# STM32F303xE register map
File version: 1.0
Registers are 32-bit, read-write, reset 0x0 unless marked. A register's access mark holds for its fields unless they carry their own. Offsets are from the block's base; [hi:lo] are bit positions; {n}, {i} and the like mark numbered series.

## SYSCFG — System configuration controller
Base 0x40010000
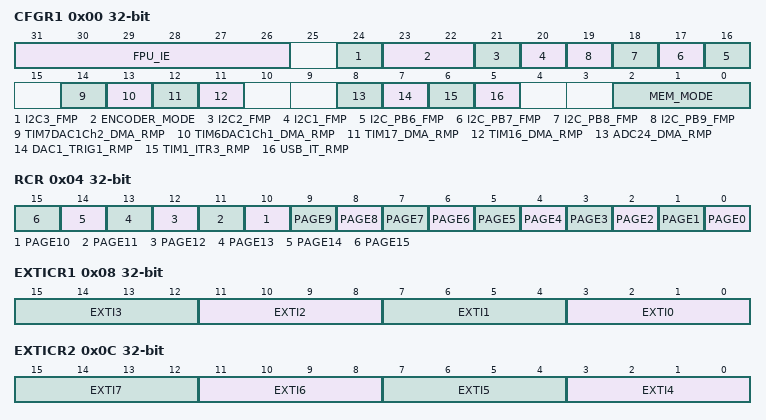
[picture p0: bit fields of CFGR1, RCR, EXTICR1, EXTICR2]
0x00 CFGR1 — SYSCFG configuration register 1
  [31:26] FPU_IE — Floating Point Unit Interrupt Enable
  [24] I2C3_FMP — I2C3 Fast mode plus
  [23:22] ENCODER_MODE
  [21] I2C2_FMP — I2C2 Fast mode plus
  [20] I2C1_FMP — I2C1 Fast mode plus
  [n+10] I2C_PB{n}_FMP (n=6..9) — I2C PB{n} Fast mode plus
  [14] TIM7DAC1Ch2_DMA_RMP — Timer 7 / DAC1 Ch2 DMA remap
  [13] TIM6DAC1Ch1_DMA_RMP — Timer 6 / DAC1 Ch1 DMA remap
  [12] TIM17_DMA_RMP — Timer 17 DMA remap
  [11] TIM16_DMA_RMP — Timer 16 DMA remap
  [8] ADC24_DMA_RMP — ADC2 and ADC4 DMA remap
  [7] DAC1_TRIG1_RMP — DAC1 Trigger1 remap
  [6] TIM1_ITR3_RMP — Timer 1 ITR3 selection
  [5] USB_IT_RMP — USB interrupt remap
  [2:0] MEM_MODE — SYSCFG_Memory Remap Config
    0=FLASH; 1=SYSTEMFLASH; 3=SRAM; 4=FMC
0x04 RCR — SYSCFG CCM SRAM protection register
  [n] PAGE{n} (n=0..15) — ICODE SRAM Write protection page {n}
0x08 EXTICR1 — SYSCFG external interrupt configuration registers
  [4n+3:4n] EXTI{n} (n=0..3) — EXTI {n} configuration
0x0C EXTICR2 — SYSCFG external interrupt configuration registers
  [4n-13:4n-16] EXTI{n} (n=4..7) — EXTI {n} configuration
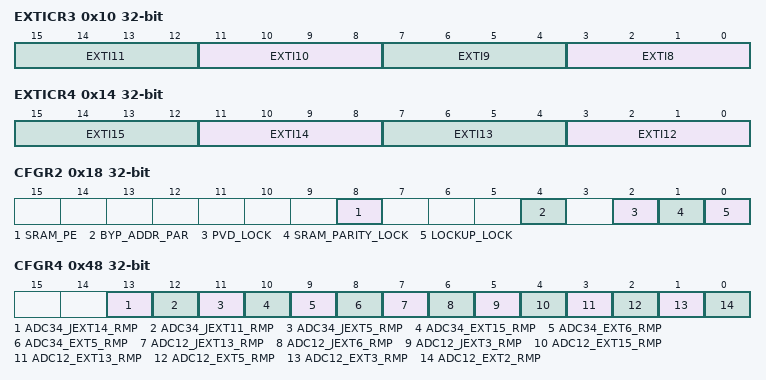
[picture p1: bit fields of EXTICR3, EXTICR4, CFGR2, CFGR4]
0x10 EXTICR3 — SYSCFG external interrupt configuration registers
  [4n-29:4n-32] EXTI{n} (n=8..11) — EXTI {n} configuration
0x14 EXTICR4 — SYSCFG external interrupt configuration registers
  [4n-45:4n-48] EXTI{n} (n=12..15) — EXTI {n} configuration
0x18 CFGR2 — SYSCFG configuration register 2
  [8] SRAM_PE — SRAM Parity error flag
  [4] BYP_ADDR_PAR — Disables the address parity check on RAM
  [2] PVD_LOCK — Enables and locks the PVD connection with TIMx Break Input, as well as the PVDE and PLS[2:0] in the PWR_CR register
  [1] SRAM_PARITY_LOCK — Enables and locks the SRAM_PARITY error signal with Break Input of TIMx
  [0] LOCKUP_LOCK — Enables and locks the LOCKUP (Hardfault) output of CortexM4 with Break Input of TIMx
0x48 CFGR4 — SYSCFG configuration register 4
  [13] ADC34_JEXT14_RMP — ADC34 injected channel JEXT14 remap
  [12] ADC34_JEXT11_RMP — ADC34 injected channel JEXT11 remap
  [11] ADC34_JEXT5_RMP — ADC34 injected channel JEXT5 remap
  [10] ADC34_EXT15_RMP — ADC34 regular channel EXT15 remap
  [9] ADC34_EXT6_RMP — ADC34 regular channel EXT6 remap
  [8] ADC34_EXT5_RMP — ADC34 regular channel EXT5 remap
  [7] ADC12_JEXT13_RMP — ADC12 injected channel JEXT13 remap
  [6] ADC12_JEXT6_RMP — ADC12 injected channel JEXT6 remap
  [5] ADC12_JEXT3_RMP — ADC12 injected channel JEXT3 remap
  [4] ADC12_EXT15_RMP — ADC12 regular channel EXT15 remap
  [3] ADC12_EXT13_RMP — ADC12 regular channel EXT13 remap
  [2] ADC12_EXT5_RMP — ADC12 regular channel EXT5 remap
  [1] ADC12_EXT3_RMP — ADC12 regular channel EXT3 remap
  [0] ADC12_EXT2_RMP — ADC12 regular channel EXT2 remap

## COMP — Analog Comparators
Base 0x4001001C
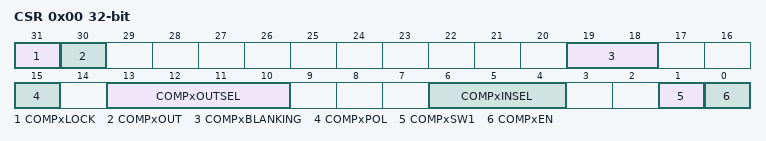
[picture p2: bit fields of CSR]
0x00 CSR — COMP control and status register
  [31] COMPxLOCK
  [30] COMPxOUT — COMPx output level
  [19:18] COMPxBLANKING
  [15] COMPxPOL — COMPx output polarity
    0=NONINVERTED (COMP output polarity is not inverted: comparator output is high when the plus (non-inverting) input is at a higher voltage than the minus (inverting) input); 1=INVERTED (COMP output polarity is inverted: comparator output is low when the plus (non-inverting) input is at a lower voltage than the minus (inverting) input)
  [13:10] COMPxOUTSEL — COMPx output select
    0=NONE (COMP output is not connected to other peripherals (except GPIO and EXTI that are always connected to COMP output) (specific to COMP instance: COMP2)); 1=TIM1_BKIN (COMP output connected to TIM1 break input (BKIN)); 2=TIM1_BKIN2 (COMP output connected to TIM1 break input 2 (BKIN2)); 5=TIM1_TIM8_BKIN2 (COMP output connected to TIM1 break input 2 and TIM8 break input 2 (BKIN2)); 3=TIM8_BKIN (COMP output connected to TIM8 break input (BKIN)); 4=TIM8_BKIN2 (COMP output connected to TIM8 break input 2 (BKIN2)); 12=TIM20_BKIN (COMP output connected to TIM8 break input (BKIN)); 13=TIM20_BKIN2 (COMP output connected to TIM8 break input 2 (BKIN2)); 14=TIM1_TIM8_TIM20_BKIN2 (COMP output connected to TIM1 break input 2, TIM8 break input 2 and TIM20 break input 2 (BKIN2)); 6=TIM1_OCCLR_COMP1_2_3_7 (COMP output connected to TIM1 OCREF clear (specific to COMP instance: COMP1, COMP2, COMP3, COMP7)); 9=TIM2_OCCLR_COMP1_2_3 (COMP output connected to TIM2 OCREF clear. Caution: Parameter specific to COMP instances, defined with generic naming, not taking into account COMP instance constraints. Refer to literal definitions above for COMP instance constraints.); 11=TIM3_OCCLR_COMP1_2_4_5 (COMP output connected to TIM3 OCREF clear (specific to COMP instance: COMP1, COMP2, COMP4, COMP5)); 7=TIM8_OCCLR_COMP4_5_6_7 (COMP output connected to TIM8 OCREF clear (specific to COMP instance: COMP4, COMP5, COMP6, COMP7)); 8=TIM2_IC4_COMP1_2 (COMP output connected to TIM2 input capture 4 (specific to COMP instance: COMP2)); 10=TIM3_IC1_COMP1_2 (COMP output connected to TIM3 input capture 1 (specific to COMP instance: COMP2)); 15=TIM20_OCCLR_COMP2 (COMP output connected to TIM20 OCREF clear (specific to COMP instance: COMP2))
  [6:4] COMPxINSEL — COMPx inverting input select
    0=MINUS_1_4VREFINT (Comparator input minus connected to 1/4 VrefInt); 1=MINUS_1_2VREFINT (Comparator input minus connected to 1/2 VrefInt); 2=MINUS_3_4VREFINT (Comparator input minus connected to 3/4 VrefInt); 3=VREFINT (Comparator input minus connected to VrefInt); 4=DAC1_CH1 (Comparator input minus connected to DAC1 channel 1 (DAC_OUT1)); 5=DAC1_CH2 (Comparator input minus connected to DAC1 channel 2 (DAC_OUT2)); 6=IO1 (Comparator input minus connected to IO1 (pin PA2 for COMP2)); 7=IO2 (Comparator input minus connected to IO2 (PB12 for COMP3, PB2 for COMP4, PB10 for COMP5, PB15 for COMP6 (COMP instance availability depends on the selected device)))
  [1] COMPxSW1 — COMPx SW1 switch control
  [0] COMPxEN — COMPx enable
